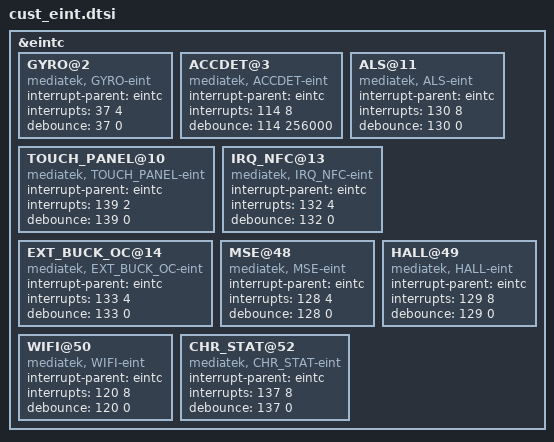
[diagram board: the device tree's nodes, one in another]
/*
 * Generated by MTK SP DrvGen Version 03.13.6 for MT6752. Copyright MediaTek Inc. (C) 2013.
 * Thu Sep 17 02:16:34 2015
 * Do Not Modify the File.
 */

/*************************
 * EINT DTSI File
*************************/

&eintc {
	GYRO@2 {
		compatible = "mediatek, GYRO-eint";
		interrupt-parent = <&eintc>;
		interrupts = <37 4>;
		debounce = <37 0>;
	};

	ACCDET@3 {
		compatible = "mediatek, ACCDET-eint";
		interrupt-parent = <&eintc>;
		interrupts = <114 8>;
		debounce = <114 256000>;
	};

	TOUCH_PANEL@10 {
		compatible = "mediatek, TOUCH_PANEL-eint";
		interrupt-parent = <&eintc>;
		interrupts = <139 2>;
		debounce = <139 0>;
	};

	ALS@11 {
		compatible = "mediatek, ALS-eint";
		interrupt-parent = <&eintc>;
		interrupts = <130 8>;
		debounce = <130 0>;
	};

	IRQ_NFC@13 {
		compatible = "mediatek, IRQ_NFC-eint";
		interrupt-parent = <&eintc>;
		interrupts = <132 4>;
		debounce = <132 0>;
	};

	EXT_BUCK_OC@14 {
		compatible = "mediatek, EXT_BUCK_OC-eint";
		interrupt-parent = <&eintc>;
		interrupts = <133 4>;
		debounce = <133 0>;
	};

	MSE@48 {
		compatible = "mediatek, MSE-eint";
		interrupt-parent = <&eintc>;
		interrupts = <128 4>;
		debounce = <128 0>;
	};

	HALL@49 {
		compatible = "mediatek, HALL-eint";
		interrupt-parent = <&eintc>;
		interrupts = <129 8>;
		debounce = <129 0>;
	};

	WIFI@50 {
		compatible = "mediatek, WIFI-eint";
		interrupt-parent = <&eintc>;
		interrupts = <120 8>;
		debounce = <120 0>;
	};

	CHR_STAT@52 {
		compatible = "mediatek, CHR_STAT-eint";
		interrupt-parent = <&eintc>;
		interrupts = <137 8>;
		debounce = <137 0>;
	};

};
